# VIDEOSYSC register map
Vendor: Texas Instruments
Peripheral module from a debugger description file (folder omap36xx).
Registers are 32-bit, access not given, reset 0x0 unless marked. A register's access mark holds for its fields unless they carry their own. Offsets are as the file gives them; lines under a group give offsets from that group; [hi:lo] are bit positions; {n}, {i} and the like mark numbered series; 'fields as' and 'values as' point back to an identical list; <NAME> marks a mode.

## VIDEOSYSC
0x00 VIDEOSYSC_REVISION ro (reset mask 0xFFFFFF00) — This register contains the IP revision code (reset value to be defined by design team for each version of the module)
  [7:0] REV — IP revision3:0 Minor revision7:4 Major revision
0x08 VIDEOSYSC_SYSCONFIG rw reset 0x1 — This register allows controlling various parameters of the video system controller module
  [0] AUTOIDLE — Internal auto-clock gating strategy0: Clock is free running1: Automatic clock gating strategy is applied
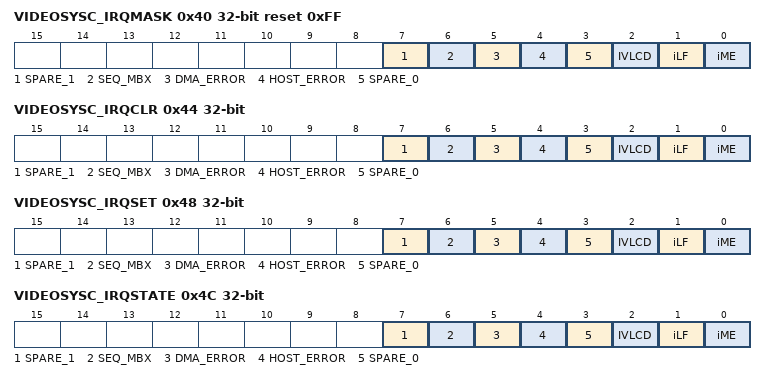
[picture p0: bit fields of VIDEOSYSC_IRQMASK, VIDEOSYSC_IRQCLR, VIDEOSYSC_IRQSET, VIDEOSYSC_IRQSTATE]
0x40 VIDEOSYSC_IRQMASK reset 0xFF — This register contains the interrupt mask bits: when.MirqN is set, input event N does not trigger the interrupt line to the sequencer (default) when .MirqN is clear, input event N triggers the interrupt line to the sequencer
  [7] SPARE_1 — Spare interrupt (reserved for future use) (access w/1toSet)
  [6] SEQ_MBX — SEQ Mailbox IRQ mask (access w/1toSet)
  [5] DMA_ERROR — DMA error IRQ mask (access w/1toSet)
  [4] HOST_ERROR — HOST error IRQ mask (access w/1toSet)
  [3] SPARE_0 — Spare interrupt (reserved for future use) (access w/1toSet)
  [2] IVLCD — iVLCD IRQ mask (access w/1toSet)
  [1] iLF — iLF IRQ mask (access w/1toSet)
  [0] iME — iME IRQ mask (access w/1toSet)
0x44 VIDEOSYSC_IRQCLR — This register is used to clear the interrupt bits in write 0: no effect write 1: clears the corresponding bit in the register and clears the interrupt line if this action clears last active and enabled (in ) input event(s). reads always return 0
  [7] SPARE_1 — Spare interrupt (reserved for future use) (access w/1toSet)
  [6] SEQ_MBX — SEQ Mailbox IRQ clear (access w/1toSet)
  [5] DMA_ERROR — DMA error IRQ clear (access w/1toSet)
  [4] HOST_ERROR — HOST error IRQ clear (access w/1toSet)
  [3] SPARE_0 — Spare interrupt (reserved for future use) (access w/1toSet)
  [2] IVLCD — iVLCD IRQ clear (access w/1toSet)
  [1] iLF — iLF IRQ clear (access w/1toSet)
  [0] iME — iME IRQ clear (access w/1toSet)
0x48 VIDEOSYSC_IRQSET — This register is used to set the interrupt bits (used to test interrupt): write 0: no effect write 1: sets the corresponding bit in the register, and triggers the interrupt line if not already active and the associated event is enabled in reads always return 0
  [7] SPARE_1 — Spare interrupt (reserved for future use) (access w/1toSet)
  [6] SEQ_MBX — SEQ Mailbox IRQ set (access w/1toSet)
  [5] DMA_ERROR — DMA error IRQ set (access w/1toSet)
  [4] HOST_ERROR — HOST error IRQ set (access w/1toSet)
  [3] SPARE_0 — Spare interrupt (reserved for future use) (access w/1toSet)
  [2] IVLCD — iVLCD IRQ set (access w/1toSet)
  [1] iLF — iLF IRQ set (access w/1toSet)
  [0] iME — iME IRQ set (access w/1toSet)
0x4C VIDEOSYSC_IRQSTATE — This register holds the interrupt status bits
  [7] SPARE_1 — Spare interrupt (reserved for future use) (access w/1toSet)
  [6] SEQ_MBX — SEQ Mailbox IRQ status (access w/1toSet)
  [5] DMA_ERROR — DMA error IRQ status (access w/1toSet)
  [4] HOST_ERROR — HOST error IRQ status (access w/1toSet)
  [3] SPARE_0 — Spare interrupt (reserved for future use) (access w/1toSet)
  [2] IVLCD — iVLCD IRQ status (access w/1toSet)
  [1] iLF — iLF IRQ status (access w/1toSet)
  [0] iME — iME IRQ status (access w/1toSet)
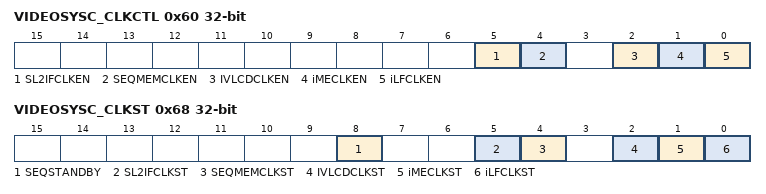
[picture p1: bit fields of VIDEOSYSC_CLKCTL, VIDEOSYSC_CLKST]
0x60 VIDEOSYSC_CLKCTL wo — Video accelerator clock control: Writing a 0 forces the module to leave the idle state (modules input clock goes active) Writing a 1 requests the module enter the idle state when no request/commands pending for the module. (Allows module input clock to be stopped). Module automatically exits the idle state and clock starts each time new requests/commands are present. Clock status can be checked in register
  [5] SL2IFCLKEN — Clock control of the SL2IF module(iLF and iME modules must be idled as well):0: Exit idle state and start SL2IF clock1: Request SL2IF logic to go to idle and stop SL2IF input clock
  [4] SEQMEMCLKEN — Clock control of the sequencer memory and slave port module:0: Exit idle state and start SEQ memory and slave port clock1: Request SEQ slave port logic to go to idle and stop SEQ clock (if SEQ in standby)
  [2] IVLCDCLKEN — Clock control of the iVLCD module:0: Exit idle state and start iVLCD clock1: Request iVLCD logic to go to idle and stop iVLCD input clock
  [1] iMECLKEN — Clock control of the iME module:0: Exit idle state and start iME clock1: Request iME logic to go to idle and stop iME input clock
  [0] iLFCLKEN — Clock control of the iLF module:0: Exit idle state and start iLF clock1: Request iLF logic to go to idle and stop iLF input clock
0x64 VIDEOSYSC_CLKDIV rw — Video accelerator sequencer clock division
  [1:0] SEQCLKDIV — Sequencer clock division control
    0=No clock division - SEQ operates at the same clock as video accelerators; 1=Clock divide by two - SEQ operates at half the video accelerators clock; 2=Clock divide by three - SEQ operates at one third the video accelerators clock; 3=Clock divide by four - SEQ operates at one fourth the video accelerators clock
0x68 VIDEOSYSC_CLKST ro — Video accelerator clock status: 0: Logic is active and the input modules input clock is running 1: Logic is idled (Clock stopped if autoidle bit also 1) Clock is only automatically stopped when logic is idled if the autoidle bit in register is set
  [8] SEQSTANDBY — SEQ is in Standby:0: SEQ is not in standby1: SEQ is in Standby
  [5] SL2IFCLKST — Clock control of the SL2IF module0: SL2IF logic is active 1: SL2IF logic is idled
  [4] SEQMEMCLKST — Clock control of the SEQ memory and slave port:0: SEQ Slave port is active 1: SEQ Slave port is Idled
  [2] IVLCDCLKST — Clock control of the iVLCD module:0: iVLCD logic is active 1: iVLCD logic is idled
  [1] iMECLKST — Clock control of the iME module:0: iME logic is active 1: iME logic is idled
  [0] iLFCLKST — Clock control of the iLF module:0: iLF logic is active 1: iLF logic is idled
